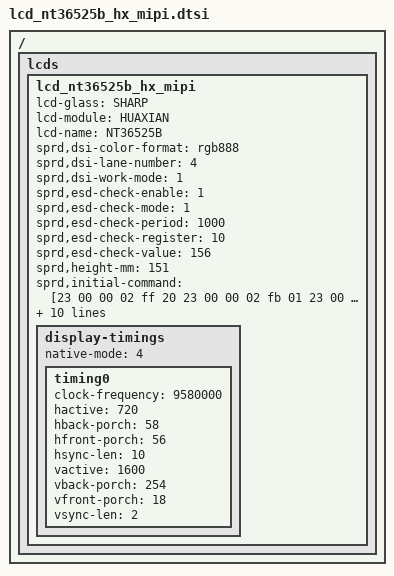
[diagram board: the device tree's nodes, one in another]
/ {
	fragment {
		target-path = "/";
		__overlay__ {
			lcds {
				lcd_nt36525b_hx_mipi {
					lcd-glass = "SHARP";
					lcd-module = "HUAXIAN";
					lcd-name = "NT36525B";
					sprd,dsi-color-format = "rgb888";
					sprd,dsi-lane-number = <4>;
					sprd,dsi-work-mode = <1>;
					sprd,esd-check-enable = <1>;
					sprd,esd-check-mode = <1>;
					sprd,esd-check-period = <1000>;
					sprd,esd-check-register = <10>;
					sprd,esd-check-value = <156>;
					sprd,height-mm = <151>;
					sprd,initial-command = [23 00 00 02 ff 20 23 00 00 02 fb 01 23 00 00 02 00 01 23 00 00 02 01 55 23 00 00 02 03 55 23 00 00 02 05 91 23 00 00 02 07 5f 23 00 00 02 08 df 23 00 00 02 0e 7d 23 00 00 02 0f 7d 23 00 00 02 1f 00 23 00 00 02 2f 82 23 00 00 02 69 a9 23 00 00 02 95 d7 23 00 00 02 96 d7 23 00 00 02 ff 24 23 00 00 02 fb 01 23 00 00 02 00 1e 23 00 00 02 02 1e 23 00 00 02 06 08 23 00 00 02 07 04 23 00 00 02 08 20 23 00 00 02 0a 0f 23 00 00 02 0b 0e 23 00 00 02 0c 0d 23 00 00 02 0d 0c 23 00 00 02 12 1e 23 00 00 02 13 1e 23 00 00 02 14 1e 23 00 00 02 16 1e 23 00 00 02 18 1e 23 00 00 02 1c 08 23 00 00 02 1d 04 23 00 00 02 1e 20 23 00 00 02 20 0f 23 00 00 02 21 0e 23 00 00 02 22 0d 23 00 00 02 23 0c 23 00 00 02 28 1e 23 00 00 02 29 1e 23 00 00 02 2a 1e 23 00 00 02 2f 06 23 00 00 02 37 66 23 00 00 02 39 00 23 00 00 02 3a 05 23 00 00 02 3b a5 23 00 00 02 3d 91 23 00 00 02 3f 48 23 00 00 02 47 44 23 00 00 02 49 00 23 00 00 02 4a 05 23 00 00 02 4b a5 23 00 00 02 4c 91 23 00 00 02 4d 12 23 00 00 02 4e 34 23 00 00 02 55 83 23 00 00 02 56 44 23 00 00 02 5a 05 23 00 00 02 5b a5 23 00 00 02 5c 00 23 00 00 02 5d 00 23 00 00 02 5e 06 23 00 00 02 5f 00 23 00 00 02 60 80 23 00 00 02 61 90 23 00 00 02 64 11 23 00 00 02 85 00 23 00 00 02 86 51 23 00 00 02 92 a7 23 00 00 02 93 12 23 00 00 02 94 0e 23 00 00 02 ab 00 23 00 00 02 ac 00 23 00 00 02 ad 00 23 00 00 02 af 04 23 00 00 02 b0 05 23 00 00 02 b1 a2 23 00 00 02 ff 25 23 00 00 02 fb 01 23 00 00 02 0a 82 23 00 00 02 0b 16 23 00 00 02 0c 01 23 00 00 02 17 82 23 00 00 02 18 06 23 00 00 02 19 0f 23 00 00 02 58 00 23 00 00 02 59 00 23 00 00 02 5a 40 23 00 00 02 5b 80 23 00 00 02 5c 00 23 00 00 02 5d 05 23 00 00 02 5e a5 23 00 00 02 5f 05 23 00 00 02 60 a5 23 00 00 02 61 05 23 00 00 02 62 a5 23 00 00 02 65 05 23 00 00 02 66 a2 23 00 00 02 c0 03 23 00 00 02 ca 1c 23 00 00 02 cb 18 23 00 00 02 cc 1c 23 00 00 02 d4 cc 23 00 00 02 d5 11 23 00 00 02 d6 18 23 00 00 02 ff 26 23 00 00 02 fb 01 23 00 00 02 00 a0 23 00 00 02 ff 27 23 00 00 02 fb 01 23 00 00 02 13 00 23 00 00 02 15 b4 23 00 00 02 1f 55 23 00 00 02 26 0f 23 00 00 02 c0 18 23 00 00 02 c1 f2 23 00 00 02 c2 00 23 00 00 02 c3 00 23 00 00 02 c4 f2 23 00 00 02 c5 00 23 00 00 02 c6 00 23 00 00 02 c7 03 23 00 00 02 ff 23 23 00 00 02 fb 01 23 00 00 02 00 00 23 00 00 02 04 00 23 00 00 02 07 20 23 00 00 02 08 0f 23 00 00 02 09 00 23 00 00 02 12 b4 23 00 00 02 15 e9 23 00 00 02 16 0b 23 00 00 02 ff e0 23 00 00 02 fb 01 23 00 00 02 25 11 23 00 00 02 4e 01 23 00 00 02 ff 10 23 00 00 02 fb 01 23 00 00 02 ba 03 23 00 00 02 53 24 23 00 00 02 51 88 23 00 00 02 35 00 39 00 00 03 68 00 01 23 78 00 01 11 23 50 00 01 29];
					sprd,is_ic_nt36525b = <1>;
                                        sprd,nt36525b_is_hx_flag = <1>;
                                        sprd,phy-bit-clock = <658784>;
                                        sprd,phy-escape-clock = <20000>;
                                        sprd,reset-on-sequence = <1 10 0 10 1 20>;
                                        sprd,sleep-in-command = [23 50 00 01 28 23 78 00 01 10];
                                        sprd,sleep-out-command = [23 78 00 01 11 23 50 00 01 29];
                                        sprd,width-mm = <68>;

                                        display-timings {
                                           native-mode = <4>;

                                        timing0 {
                                       clock-frequency = <9580000>;
                                       hactive = <720>;
                                       hback-porch = <58>;
                                       hfront-porch = <56>;
                                       hsync-len = <10>;
                                       vactive = <1600>;
                                       vback-porch = <254>;
                                       vfront-porch = <18>;
                                       vsync-len = <2>;

					       };
					};
				};
			};
		};
	};
};



